# CH32H417 register map
Vendor: WCH Ltd.; File version: 1.2
Registers are 32-bit, read-write, reset 0x0 unless marked. A register's access mark holds for its fields unless they carry their own. Offsets are from the block's base; [hi:lo] are bit positions; {n}, {i} and the like mark numbered series; 'fields as' and 'values as' point back to an identical list.

## USBSS — USB3.0 ultra-high speed host /device controller
Base 0x40034000
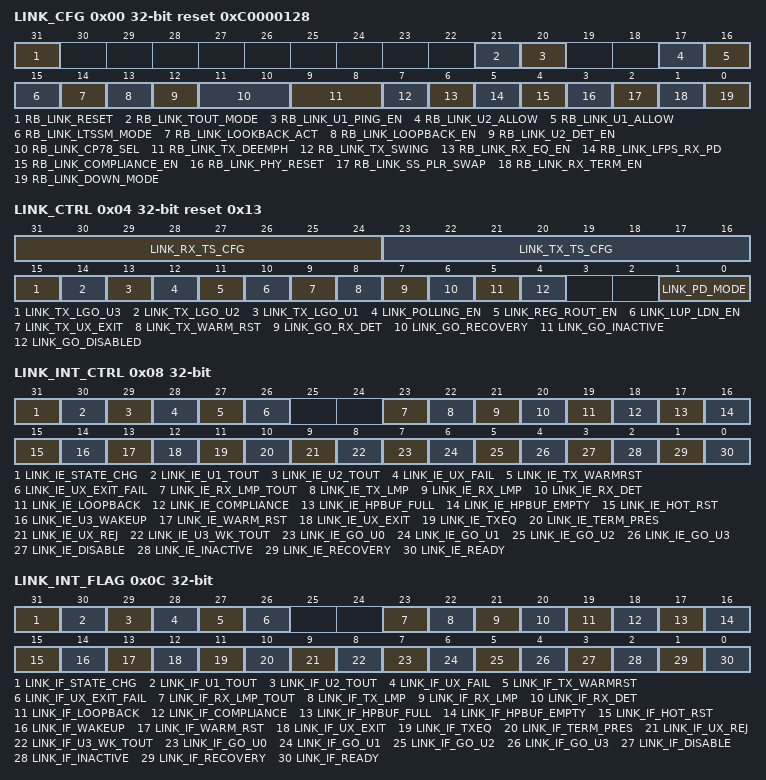
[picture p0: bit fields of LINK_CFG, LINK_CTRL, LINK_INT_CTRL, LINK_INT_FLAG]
0x00 LINK_CFG reset 0xC0000128 — LINK Configuration Register
  [31] RB_LINK_RESET — LINK reset, including the reset state machine and all interrupt flags, is highly effective
  [21] RB_LINK_TOUT_MODE — SPEC configure
  [20] RB_LINK_U1_PING_EN — Send PING_FPFS under U1 to enable
  [17] RB_LINK_U2_ALLOW — High validity, after receiving the LGO_U2, the response LXU allows to enter the U2 state, otherwise after receiving the LGO_U2, the response LXU refuses to enter the U2 state.
  [16] RB_LINK_U1_ALLOW — High validity, after receiving the LGO_U1, the response LAU allows to enter the U1 state, otherwise, after receiving the LGO_U1, the response LXU refuses to enter the U1 state
  [15] RB_LINK_LTSSM_MODE — The link state machine enters DISABLE mode
  [14] RB_LINK_LOOKBACK_ACT — It is used in LOOPBACK mode for the LOOPBACK master to control the pattern transmission (the LOOPBACK slave keeps 0), and the ACT is a high-level signal that lasts for a period of time.
  [13] RB_LINK_LOOPBACK_EN — The LOOPBACK enable bit is allowed, which is highly active, and can be used with the LOOKBACK enable in TX/RX_TS_CFG [3], both of which are valid before LINK can enter the LOOKBACK mode (used to enable the data loopback and error counting of the LOOPBACK slave, and the LOOPBACK master remains 0).
  [12] RB_LINK_U2_DET_EN — Detection mode of connected devices in U2 state
  [11:10] RB_LINK_CP78_SEL — In Compliance Pattern 7/8, send a length of consecutive 0 or consecutive 1
  [9:8] RB_LINK_TX_DEEMPH — Transmitter de-emphasis control
  [7] RB_LINK_TX_SWING — The transmitter signal swing control, low swing power consumption, but affect the transmission distance
  [6] RB_LINK_RX_EQ_EN — Receiver equalization enable control, optional protocol specifications
  [5] RB_LINK_LFPS_RX_PD — LFPS receive control, this bit is 1 to disable LFPS reception
  [4] RB_LINK_COMPLIANCE_EN — POLLING_LFPS timeout is in COMPLIANCE mode
  [3] RB_LINK_PHY_RESET — The PIPE interface is reset
  [2] RB_LINK_SS_PLR_SWAP — Exchange SSTX and SSRX polarities as follows
  [1] RB_LINK_RX_TERM_EN — Receiver Termination Resistance Control
  [0] RB_LINK_DOWN_MODE — Peripheral Type
0x04 LINK_CTRL access per field reset 0x13 — LINK control registers
  [31:24] LINK_RX_TS_CFG ro — Received Link Control
  [23:16] LINK_TX_TS_CFG rw — Send the link configuration of the TS1/TS2 training sequence
  [15] LINK_TX_LGO_U3 rw — After the bit is valid, the LGO_U3 is transmitted, and the hardware is automatically cleared
  [14] LINK_TX_LGO_U2 rw — After the bit is valid, the LGO_U2 is sent, the high is active, and the hardware is automatically cleared
  [13] LINK_TX_LGO_U1 rw — After the bit is valid, the LGO_U1 is sent, the high is active, and the hardware is automatically cleared
  [12] LINK_POLLING_EN rw — If the TERM is detected by the SS.RX_DETECT, a POLLING handshake will be performed after the software sets the bit to be valid
  [11] LINK_REG_ROUT_EN rw — Enable the routing function of the HUB, which is highly effective, with registers and no interfaces
  [10] LINK_LUP_LDN_EN rw — In the U0 state, if there is no data, whether to send LUP and LDN packets every 10us
  [9] LINK_TX_UX_EXIT rw — High validity, hardware automatic zeroing
  [8] LINK_TX_WARM_RST rw — High validity, cleared by software. A valid bit will send a warm-reset
  [7] LINK_GO_RX_DET rw — Before setting this bit, the PD_MODE should be set to P2 mode, and the LINK should be set to enter the SS.RX_DETECT, and the software will query TERM_PRESENT to know whether there is a connection or whether the connection is disconnected. High effectiveness, automatic clearing.
  [6] LINK_GO_RECOVERY rw — SET THE LINK TO ENTER SS.RECOVERY, WHICH IS HIGHLY EFFECTIVE, AND THE HARDWARE IS AUTOMATICALLY CLEARED.
  [5] LINK_GO_INACTIVE rw — SET THE LINK TO ENTER SS.INACTIVE, WHICH IS HIGHLY VALID, AND THE HARDWARE IS AUTOMATICALLY CLEARED
  [4] LINK_GO_DISABLED rw — SET LINK TO ENTER SS.DISABLED, WHICH IS HIGHLY VALID, AND REQUIRES SOFTWARE TO CLEAR
  [1:0] LINK_PD_MODE rw — Configure the current power mode of the PHY, corresponding to PO/P1/P2/P3 in the PIPE
0x08 LINK_INT_CTRL — LINK interrupt enable register
  [31] LINK_IE_STATE_CHG — Link State Machine Change Flag Interrupt Enabled
  [30] LINK_IE_U1_TOUT — U1 Timeout Interrupt Enabled
  [29] LINK_IE_U2_TOUT — U2 Timeout Interrupt Enabled
  [28] LINK_IE_UX_FAIL — UX Conversion Failure Interrupt Enabled
  [27] LINK_IE_TX_WARMRST — Send warm_reset end interrupt enabled
  [26] LINK_IE_UX_EXIT_FAIL — Exit UX failed to interrupt enabled
  [23] LINK_IE_RX_LMP_TOUT — Receive LMP Timeout Interrupt Enabled
  [22] LINK_IE_TX_LMP — If you successfully enter U0, you can send an HP packet to interrupt enable
  [21] LINK_IE_RX_LMP — Received Link Command Flag Interrupt Enabled
  [20] LINK_IE_RX_DET — The link enters the Rx.Detect state and is interrupted
  [19] LINK_IE_LOOPBACK — The link goes into loopback mode for testing and error isolation interrupt enablement
  [18] LINK_IE_COMPLIANCE — The link enters the compliance test, and the interrupt is enabled by the compatibility test or the physical layer conformance test
  [17] LINK_IE_HPBUF_FULL — BUF sends FIFO full interrupt enable
  [16] LINK_IE_HPBUF_EMPTY — BUF sends FIFO null interrupt enable
  [15] LINK_IE_HOT_RST — hot reset, which uses the reset interrupt enable of the TS1/TS2 ordered set
  [14] LINK_IE_U3_WAKEUP — In the U3 state, the Low Frequency Periodic Signal (LFPS) is received to wake up interrupt enabled
  [13] LINK_IE_WARM_RST — Warm reset (not connected) interrupt enabled with LPFS
  [12] LINK_IE_UX_EXIT — Request to exit UX is received Interrupt Enable
  [11] LINK_IE_TXEQ — LINK enters the POLLING_RXEQ for receiver equalization training interrupt enable
  [10] LINK_IE_TERM_PRES — LINK enters the RX_DETECT to detect the impedance of the remote receiver trace segment and detect the interrupt enabled
  [9] LINK_IE_UX_REJ — Transmit LGO_ Ux, receive LXU interrupt enabled that refuses to enter the Ux
  [8] LINK_IE_U3_WK_TOUT — Interrupt the U3 command when requesting to exit U3 command timeout
  [7] LINK_IE_GO_U0 — LINK is interrupted at U0 to enable the following
  [6] LINK_IE_GO_U1 — LINK is interrupted at U1 to enable the following
  [5] LINK_IE_GO_U2 — LINK is interrupted at U2 and enabled
  [4] LINK_IE_GO_U3 — LINK is enabled when the U3 interrupt is enabled
  [3] LINK_IE_DISABLE — LINK is disabled, interrupt enabled
  [2] LINK_IE_INACTIVE — LINK is enabled on INACTIVE interrupt
  [1] LINK_IE_RECOVERY — DUE TO ERROR LINK IN RECOVERY INTERRUPTED ENABLED
  [0] LINK_IE_READY — LINK is initialized, including two ports before (Header Sequence Number Advertisement) and (RX Headr Buffer Credit Advertisement) interrupt enabled
0x0C LINK_INT_FLAG — LINK Interrupt Flag Register
  [31] LINK_IF_STATE_CHG — link_reset reset to 0
  [30] LINK_IF_U1_TOUT — U1 timeout interrupted
  [29] LINK_IF_U2_TOUT — U2 timeout interrupted
  [28] LINK_IF_UX_FAIL — Enter the Ux failed to interrupt
  [27] LINK_IF_TX_WARMRST — send warm_reset to end interrupt
  [26] LINK_IF_UX_EXIT_FAIL — Exit UX fails to interrupt
  [23] LINK_IF_RX_LMP_TOUT — After the LINK initialization is complete, the Port Capabilities/Configuration LMPs timeout (20us) interrupt flag is exchanged.
  [22] LINK_IF_TX_LMP — After the LINK initialization is completed, the software is configured to send Port Capabilities LMP for port capability switching
  [21] LINK_IF_RX_LMP — Receive LMP Interrupt Flag
  [20] LINK_IF_RX_DET — After entering the RX_DETECT state interrupt flag, this position 1, the software sets the PWR_MODE to P2, ready for RX_DETECT
  [19] LINK_IF_LOOPBACK — LINK enters the LOOPBACK state and the LINK is interrupted.
  [18] LINK_IF_COMPLIANCE — LINK enters the COMPLIANCE state with an outage flag.
  [17] LINK_IF_HPBUF_FULL — Header Packet buffer full interrupt flag.
  [16] LINK_IF_HPBUF_EMPTY — he device receives the HOT RESET interrupt flag
  [15] LINK_IF_HOT_RST — The device receives the HOT RESET interrupt flag
  [14] LINK_IF_WAKEUP — The power supply is in P3 mode and the LFPS signal interrupt flag is detected.
  [13] LINK_IF_WARM_RST — The WARM RESET status change (active-> inactive, or invalid->active) interrupt flag received by the device.
  [12] LINK_IF_UX_EXIT — LINK receives the LFPS ready to exit U1/U2/U3 request interrupt flag
  [11] LINK_IF_TXEQ — LINK enters TXEQ state interrupt flag: INDICATE THAT THE POLLING HANDSHAKE IS COMPLETE, AND WAIT FOR THE SOFTWARE TO SET THE PWR_MODE TO P0 IN ORDER TO ENTER THE TXEQ PHASE.
  [10] LINK_IF_TERM_PRES — The TERM disconnected or disconnected flag was detected
  [9] LINK_IF_UX_REJ — LINK refuses to enter the low-power mode (U1/U2) interrupt flag.
  [8] LINK_IF_U3_WK_TOUT — Wake up from U3 to timeout interrupt flag (10ms).
  [7-n] LINK_IF_GO_U{n} (n=0..3) — LINK enters the U{n} state interrupt flag.
  [3] LINK_IF_DISABLE — LINK INTO SS.DISABLE STATE INTERRUPT FLAG
  [2] LINK_IF_INACTIVE — LINK ENTERS THE SS.ACTIVE STATE INTERRUPT FLAG
  [1] LINK_IF_RECOVERY — LINK INTO THE SS.RECOVERY STATE INTERRUPT FLAG
  [0] LINK_IF_READY — LINK enters the U0 state and completes LINK initialization of the interrupt flag.
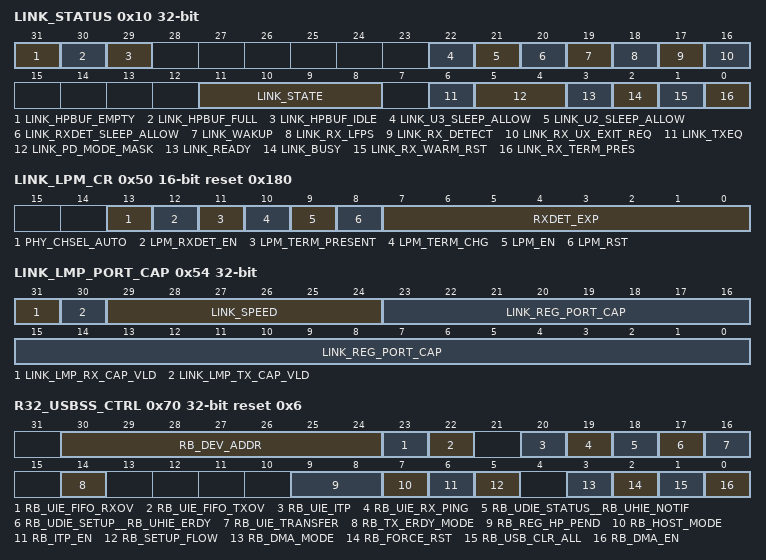
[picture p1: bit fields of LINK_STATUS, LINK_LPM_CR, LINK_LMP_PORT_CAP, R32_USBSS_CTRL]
0x10 LINK_STATUS ro
  [31] LINK_HPBUF_EMPTY — The HP buffer is empty.
  [30] LINK_HPBUF_FULL — The HP buffer is full.
  [29] LINK_HPBUF_IDLE — BUF sends the status of the FIFO IDLE
  [22] LINK_U3_SLEEP_ALLOW — The link is in the U3 state and sleep is allowed
  [21] LINK_U2_SLEEP_ALLOW — The link is in the U2 state and sleep is allowed.
  [20] LINK_RXDET_SLEEP_ALLOW — The link is in the RXDET state, allowing sleep.
  [19] LINK_WAKUP — A link wake-up signal is received.
  [18] LINK_RX_LFPS — The link receives an LFPS signal.
  [17] LINK_RX_DETECT — The link is at P2 and is in rx_detect.
  [16] LINK_RX_UX_EXIT_REQ — Received a request to exit Ux
  [11:8] LINK_STATE — Link Status
  [6] LINK_TXEQ — The link is in POLLING_RXEQ.
  [5:4] LINK_PD_MODE_MASK — Link Power Status
  [3] LINK_READY — When the LINK enters the U0 state, the position 1 exits the U0 state after the initialization (broadcast) is completed, and the bit is automatically cleared.
  [2] LINK_BUSY — When the LINK is busy, the bit is 1 when the switchover is PD_MODE, and the hardware will automatically clear the link after the switchover is completed.
  [1] LINK_RX_WARM_RST — A valid warm-reset signal is received from the host (the hardware automatically pulls up after receiving the host's warm_reset 18ms).
  [0] LINK_RX_TERM_PRES — After RX_DETECT, if a receive termination resistor is present, the bit is 1
0x17 LINK_ITP_PRE 8-bit ro reset 0x80 — LINK ITP Timeout Mode Register
  [7:0] ITP_PRE — ITP Timeout Mode
0x1D LINK_U2_INACT_TIMER 8-bit — LINK U2 Inactivity Timeout Counter Threshold Register
  [7:0] U2_INACTIVE_TIMER — The value of the inactivity timeout counter threshold for U2
0x28 LINK_U1_WKUP_FILTER 8-bit reset 0x4A — U1 wakes up the LFPS Duration Register
  [7:0] U1_WKUP_FILTER — The duration of the LFPS received by U1 when exiting. When the receiving LFPS reaches this time, the received U1 EXIT is considered valid, and the handshake is successful when the transmitting LFPS_last is raised, which is 600ns by default U1_WKUP_FILTER [7]: the unit of time that controls the U1_WKUP_FILTER [6:0]
0x2C LINK_U2_WKUP_FILTER 8-bit reset 0x2 — U2 wakes up the LFPS Duration Register
  [7:0] U2_WKUP_FILTER — When the receiving LFPS reaches this time, the sending LFPS_last is pulled up and the handshake is successful, and the received U2 EXIT can be considered valid with the duration of (n)us, the default is 2us.
0x30 LINK_U3_WKUP_FILTER 8-bit reset 0x64 — U3 wakes up the LFPS validity duration register
  [7:0] U3_WKUP_FILTER — When the receiving LFPS reaches this time, the LFPS_last is raised, and the handshake is successful, and the received U3 EXIT is considered valid for (n)us, with a default of 100us.
0x40 LINK_ISO_DLY 16-bit reset 0x28 — LINK Synchronous Delay Register
  [15:0] LINK_ISOCH_DLY — The delay time for the serial bitstream to parse to the parallel data is 40ns by default, and the SET ISOCH DELAY host sends this information to the device when enumerated, and writes the delay information to the register as the device, and the lower 3 bits of the register are invalid (because the clock frequency is 125MHz, the delay time needs to be set to 8*n).
0x50 LINK_LPM_CR 16-bit reset 0x180 — Link Power Management Registers
  [13] PHY_CHSEL_AUTO — Automatic selection of the PHY layer transceiver channel type
  [12] LPM_RXDET_EN — When the lpm count reaches the expected value RXDET_EXP it is confirmed that a device is connected to the PHY, this bit is raised.
  [11] LPM_TERM_PRESENT — The PHY layer detects a device connection.
  [10] LPM_TERM_CHG — The connected device changes, plugs in the device or unplugs the device.
  [9] LPM_EN — LPM Enable
  [8] LPM_RST — Reset signal for LPM related register
  [7:0] RXDET_EXP — Detects external device counter registers.
0x54 LINK_LMP_PORT_CAP ro — PORT_CAP Registers
  [31] LINK_LMP_RX_CAP_VLD — A valid PORT_CAP-LMP is received, and the protocol stipulates that the two LINK parties exchange PORT_CAP-LMP within 20 years after entering the U0 state.
  [30] LINK_LMP_TX_CAP_VLD — PORT Capability configuration completion flag
  [29:24] LINK_SPEED — [24] Position 1, indicating that the supported device supports USB3.2 Gen1 (5Gbps).
  [23:0] LINK_REG_PORT_CAP — link port configure
0x58 LINK_LMP_RX_DATA0 ro — LMP receives data 0 register
  [31:0] LINK_LMP_RX_DATA0 — Once the LMP is received, the HP data is stored in this register [31:0]
0x5C LINK_LMP_RX_DATA1 ro — LMP receives data 1 register
  [31:0] LINK_LMP_RX_DATA1 — Once the LMP is received, the HP data is stored in this register [63:32]
0x60 LINK_LMP_RX_DATA2 ro — LMP receives data 2 register
  [31:0] LINK_LMP_RX_DATA1 — Once the LMP is received, the HP data is stored in this register [95:64]
{0x64+4i} LINK_LMP_TX_DATA{i} (i=0..2) — USB Custom HP Data {i} Register
  [31:0] LINK_LMP_TX_DATA{i} — The data of the user-defined HP is sent [{32i+31}:{32i}]
0x70 R32_USBSS_CTRL reset 0x6 — USBSS Control Register
  [30:24] RB_DEV_ADDR — Host Mode
  [23] RB_UIE_FIFO_RXOV — Receive FIFO overflow interrupt enabled
  [22] RB_UIE_FIFO_TXOV — Sending FIFO overflow interrupt enables
  [20] RB_UIE_ITP — Send ITP to complete interrupt enable
  [19] RB_UIE_RX_PING — Interrupt Enabled for Receiving PING-TP
  [18] RB_UDIE_STATUS__RB_UHIE_NOTIF — Device mode: Receiving STATUS transaction completion interrupt enabled; Host mode: Interrupt enabled for receiving DEV_NOTIF-TP
  [17] RB_UDIE_SETUP__RB_UHIE_ERDY — Device Mode: Receive SETUP Transaction Completion Interrupt Enabled; Host mode:Receive SETUP Transaction Completion Interrupt Enabled
  [16] RB_UIE_TRANSFER — USB Transaction Completion Interrupt Enabled
  [14] RB_TX_ERDY_MODE — Use in device mode
  [9:8] RB_REG_HP_PEND — Packet Pending control bit for sending TP/DP packets
  [7] RB_HOST_MODE — USB Operating Mode Selection Bits
  [6] RB_ITP_EN — In host mode, send ITP enabled
  [5] RB_SETUP_FLOW — SETUP transaction throttling
  [3] RB_DMA_MODE — When DPH is transmitted in bursts, the next packet of data status
  [2] RB_FORCE_RST — The protocol layer and FIFO module are reset and need to be cleared by software.
  [1] RB_USB_CLR_ALL — Reset all software configuration registers, high validity, software clearance required
  [0] RB_DMA_EN — Enable DMA
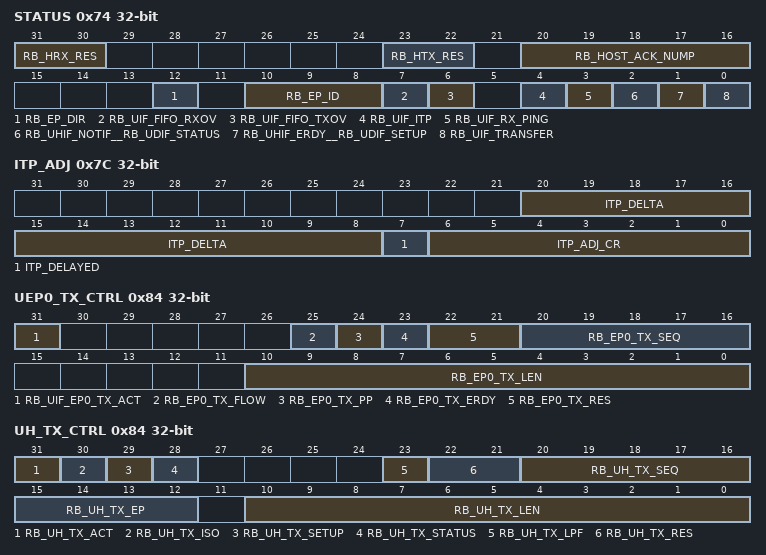
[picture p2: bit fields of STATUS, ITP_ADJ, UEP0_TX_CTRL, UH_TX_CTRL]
0x74 STATUS — USBSS Status Register
  [31:30] RB_HRX_RES — A reply TP is received from the device back
  [23:22] RB_HTX_RES — Received a reply TP from the device returning
  [20:16] RB_HOST_ACK_NUMP — This bit is invalid for synchronous transmission, and is defined as follows in Control Transfer, Block Transfer, and Interrupt Transfer
  [12] RB_EP_DIR — The direction of the endpoint that currently has an interrupt flag for transmission completion,
  [10:8] RB_EP_ID — If multiple endpoints have interrupt flags at the same time, the order of endpoint priority is as follows
  [7] RB_UIF_FIFO_RXOV — Receive FIFO overflow interrupt flag
  [6] RB_UIF_FIFO_TXOV — Send FIFO overflow interrupt flag
  [4] RB_UIF_ITP — Send the ITP Complete Interrupt flag
  [3] RB_UIF_RX_PING — Receive PING-TP Complete Interrupt Flag
  [2] RB_UHIF_NOTIF__RB_UDIF_STATUS — Host Mode: Receive DEV_NOTIF-TP Complete Interrupt Flag; Device Mode: Receive STATUS Transaction Completion Interrupt Flag
  [1] RB_UHIF_ERDY__RB_UDIF_SETUP — Host Mode: Receive ERDY-TP Complete Interrupt Flag; Device Mode: Receive SETUP Transaction Completion Interrupt Flag
  [0] RB_UIF_TRANSFER — USB Transaction Completion Interrupt Flag
0x78 ITP ro — Interval Registers for ITP packets in USB
  [13:0] REG_ITP_INTERVAL — Bus interval Counter field in the received ITP.
0x7C ITP_ADJ ro — Interval Adaptive Registers for ITP packets in USB
  [20:8] ITP_DELTA — The higher 13-bit delta of the ITS in the ITP received in device mode indicates the time difference from the start of the current ITP packet to the previous bus interval boundary.
  [7] ITP_DELAYED — In device mode, the Delayed bit of Link Control Word in the received ITP is 1 when the ITP is delayed.
  [6:0] ITP_ADJ_CR — In device mode, the Bus Interval Adjustment Control field in the received ITP should be 0 after power-on reset or device disconnection.
0x80 UEP_TX_EN 16-bit reset 0x1 — Endpoint Sends Enable Register
  [15:1] RB_EP_TX_EN — Endpoints 1~15 upload enabled
0x82 UEP_RX_EN 16-bit reset 0x1 — Endpoint Receive Enable Register
  [15:1] RB_EP_RX_EN — Endpoints 1~15 downpass enabled
0x84 UEP0_TX_CTRL access per field — Endpoint 0 sends control registers
  [31] RB_UIF_EP0_TX_ACT rw — The upload transaction is interrupted, the software writes 0 to zero, and the hardware sets 1.
  [25] RB_EP0_TX_FLOW ro — A sign that completes the NRDY-TP send (answer)
  [24] RB_EP0_TX_PP ro — The PP bit in the received ACK-TP
  [23] RB_EP0_TX_ERDY rw — ERDY received
  [22:21] RB_EP0_TX_RES rw — Response to ACK-TP
  [20:16] RB_EP0_TX_SEQ rw — The current sequence number of the endpoint, which is aotomatically reset after receiving the SETUP transaction
  [10:0] RB_EP0_TX_LEN rw — Endpoint transmits length registers with a maximum value of 512B
0x84 UH_TX_CTRL (alternate view of UEP0_TX_CTRL) — Host Transmit Control Registers
  [31] RB_UH_TX_ACT — The IN transaction completes the interrupt flag, the software writes 0 to zero, and the hardware sets 1.
  [30] RB_UH_TX_ISO — The host prepares to send ISO packets.
  [29] RB_UH_TX_SETUP — Indicates that the packet sent by the host is a Setup packet, and the setup flag is set.
  [28] RB_UH_TX_STATUS — Indicates that the packet sent by the host is STATUS TP.
  [23] RB_UH_TX_LPF — For burst transmissions, this bit simply represents the LPF/EOB of the last packet, and the LPF/EOB of the preceding packet uses a fixed value of 0.
  [22:21] RB_UH_TX_RES — Response to DPH+DPP
  [20:16] RB_UH_TX_SEQ — The SEQ _NUM for which the endpoint receives the packet, the hardware automatically adds 1, except for endpoint 0
  [15:12] RB_UH_TX_EP — Indicates the destination of the packet sent in host mode (the target endpoint number of the device)
  [10:0] RB_UH_TX_LEN — The endpoint receives the length register, which for burst transmissions indicates the packet length of the last packet of the burst transmission, and the other packets must be 1024B as specified in the protocol.
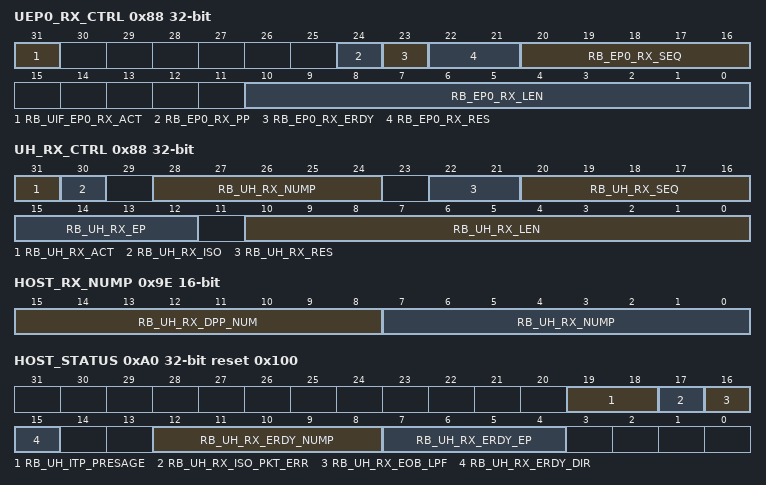
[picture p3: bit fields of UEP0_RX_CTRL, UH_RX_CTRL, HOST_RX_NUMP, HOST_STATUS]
0x88 UEP0_RX_CTRL access per field — Endpoint 0 receives control registers
  [31] RB_UIF_EP0_RX_ACT rw — Upload the transaction completion interrupt flag, the software writes 0 to zero, and the hardware sets 1
  [24] RB_EP0_RX_PP ro — PP bits in the received DPH
  [23] RB_EP0_RX_ERDY rw — ERDY received
  [22:21] RB_EP0_RX_RES rw — Response to DPH
  [20:16] RB_EP0_RX_SEQ rw — The sequence number of the endpoint expects to accept
  [10:0] RB_EP0_RX_LEN ro — The endpoint receives the length register
0x88 UH_RX_CTRL access per field (alternate view of UEP0_RX_CTRL) — Host receives control registers
  [31] RB_UH_RX_ACT rw — The OUT transaction completes the interrupt flag, the software writes 0 to zero, and the hardware sets 1
  [30] RB_UH_RX_ISO ro — Received Packets (DPP) are transmitted synchronously
  [28:24] RB_UH_RX_NUMP rw — The number of packets (DPP) that the endpoint is capable of receiving (burst transmission)
  [22:21] RB_UH_RX_RES ro — Response to DPH+DPP or STATUS-TP
  [20:16] RB_UH_RX_SEQ rw — The SEQ _NUM that the endpoint expects to receive, the hardware automatically adds 1, except for endpoint 0
  [15:12] RB_UH_RX_EP rw — Indicates the source (device endpoint number) from which the packet was received in host mode
  [10:0] RB_UH_RX_LEN ro — The endpoint receives the length register, which for burst transmissions indicates the packet length of the last packet of the burst transmission, and the other packets must be 1024B as specified in the protocol
0x8C UH_TX_DMA_U3EP0_TX_DMA — Send buffer address registers
  [31:0] U3EP0_TX_DMA — Host Mode:The start address of the host sending buffer. Device Mode:Endpoint 0 sends the start of the buffer.
0x90 UH_RX_DMA_U3EP0_RX_DMA — Receive buffer address registers
  [31:0] U3EP0_RX_DMA — Host Mode:The start address of the host receiving buffer. Device Mode:Endpoint 0 receives the start of the buffer.
0x94 UH_TX_DMA_OFS reset 0x400 — Host Transmit Address Offset Register
  [31:0] RB_UH_TX_DMA_OFS — After the host sends the DMA, the size of the DMA address offset
0x98 UH_RX_DMA_OFS reset 0x400 — Host Receive Address Offset Register
  [31:0] RB_UH_RX_DMA_OFS — After the host receives it, the DMA's address is offset by a large amount.
0x9E HOST_RX_NUMP 16-bit — The host receives the NUMP register
  [15:8] RB_UH_RX_DPP_NUM — The number of DPPs that have been accepted by the host.
  [7:0] RB_UH_RX_NUMP — The number of packets that the host expects to receive, if it is a synchronous transmission, will automatically subtract 1 from the hardware for each packet it receives.
0xA0 HOST_STATUS ro reset 0x100 — Host Status Registers
  [19:18] RB_UH_ITP_PRESAGE — In host mode, this bit indicates the time when the ITP packet was sent
  [17] RB_UH_RX_ISO_PKT_ERR — A CRC error was received for the packet (DPP) during synchronous transmission
  [16] RB_UH_RX_EOB_LPF — This bit represents the EOB/LPF status in the received packet
  [15] RB_UH_RX_ERDY_DIR — ERDY is received from the device, and the segment represents the direction of the endpoint
  [12:8] RB_UH_RX_ERDY_NUMP — ERDY received from the device, which indicates the number of packets that can be sent/received by the device's corresponding endpoint
  [7:4] RB_UH_RX_ERDY_EP — ERDY is received from the device, and the segment represents the endpoint number of the device ERDY
0xA4 HOST_TX_FC_STATUS 16-bit — The host endpoint sends flow control register
  [15:1] EPx_TX_FC — The flow control status of the host to send endpoints 1-15.
0xA6 HOST_RX_FC_STATUS 16-bit — The host endpoint receives the flow control register
  [15:1] EPx_RX_FC — The flow control status of the host to receiving endpoints 1-15
{0xA8+4i} TP_RX_DATA{i} ro (i=0..2) — DEV_NOTIF-TP Data {i} Register
  [31:0] USB3_NOTIF_DATA{i} — After the DEV_NOTIF-TP is received, the HP data is stored in this register
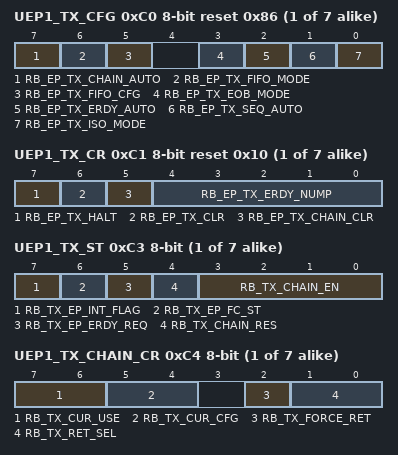
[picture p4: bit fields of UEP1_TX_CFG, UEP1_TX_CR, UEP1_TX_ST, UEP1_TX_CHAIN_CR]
{0xA0+0x20*i} UEP{i}_TX_CFG 8-bit reset 0x86 (i=1..7) — Endpoint {i} Configuration Register
  [7] RB_EP_TX_CHAIN_AUTO — CHAIN automatically switches modes, and this mode is recommended
  [6] RB_EP_TX_FIFO_MODE — If the bit is 1, the current endpoint uses FIFO mode, and the start and end addresses of the FIFO should be configured before the bit is 1.
  [5] RB_EP_TX_FIFO_CFG — Access offset address 0xC~0xF, and the operation object
  [3] RB_EP_TX_EOB_MODE — If a short packet is sent, EOB/LPF=0 in ACK-TP;If a short packet is sent, EOB/LPF=1 in ACK-TP
  [2] RB_EP_TX_ERDY_AUTO — ERDY automatic mode, the hardware will send ERDY, no software control required; It is recommended that the synchronization endpoint zero out this bit.
  [1] RB_EP_TX_SEQ_AUTO — 1: It is forbidden to write R16_EPn_ST->EP_SEQ_NUM software; 0: allows the software to write R16_EPn_ST->EP_SEQ_NUM.
  [0] RB_EP_TX_ISO_MODE — A value of 1 indicates that the current endpoint is a synchronous endpoint
{0xA1+0x20*i} UEP{i}_TX_CR 8-bit reset 0x10 (i=1..7) — Endpoint {i} control register
  [7] RB_EP_TX_HALT — Endpoint Stop, High Validity, Endpoint Stop Answering STALL to DPH.
  [6] RB_EP_TX_CLR — Write 1 clears all configuration values and status of the endpoint, except for UEP_CFG.
  [5] RB_EP_TX_CHAIN_CLR — Write 1 clears all CHAIN configuration values and statuses
  [4:0] RB_EP_TX_ERDY_NUMP — The nump field of ERDY-TP is sent by the hardware, and the value is generally set to the number of supported bursts. For example, if you support 16 bursts, the value of this field is 16.
{0xA2+0x20*i} UEP{i}_TX_SEQ 8-bit (i=1..7) — Endpoint {i} Serial Number Register
  [4:0] RB_TX_EP_SEQ_NUM — The current serial number of the endpoint, writable in non-SEQ_AUTO mode, read-only in SEQ_AUTO mode
{0xA3+0x20*i} UEP{i}_TX_ST 8-bit access per field (i=1..7) — Endpoint {i} status register
  [7] RB_TX_EP_INT_FLAG ro — The current break flag for the endpoint, the bit is read-only, and all CHAIN_IF are 0 if the bit is 0, otherwise it is 1.
  [6] RB_TX_EP_FC_ST rw — The endpoint is in the current throttling state, and write 1 is cleared to zero.
  [5] RB_TX_EP_ERDY_REQ rw — Indicates that the ERDY is currently being sent; Writing 1 to that bit will send ERDY, which is used in non-ERDY_AUTO mode.
  [4] RB_TX_CHAIN_RES ro — CHAIN response state, corresponding to 4 separate CHAINS
  [3:0] RB_TX_CHAIN_EN ro — The CHAIN enabled state, which corresponds to 4 independent CHAINS.
{0xA4+0x20*i} UEP{i}_TX_CHAIN_CR 8-bit access per field (i=1..7) — Endpoint {i} CHAIN control register
  [7:6] RB_TX_CUR_USE ro — The CHAIN serial number currently in use
  [5:4] RB_TX_CUR_CFG ro — The chain serial number of the current configuration.
  [2] RB_TX_FORCE_RET rw — This bit effectively forces the return of the selected CHAIN state machine configuration
  [1:0] RB_TX_RET_SEL rw — When the FORCE_RET is valid, this bit indicates the returned CHAIN status and configuration
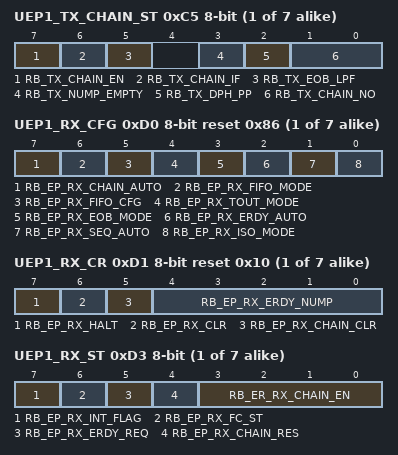
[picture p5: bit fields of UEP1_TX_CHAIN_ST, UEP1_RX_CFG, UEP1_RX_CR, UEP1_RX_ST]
{0xA5+0x20*i} UEP{i}_TX_CHAIN_ST 8-bit access per field (i=1..7) — Endpoint {i} CHAIN state register
  [7] RB_TX_CHAIN_EN ro — The currently used CHAIN enables the automatic hardware setting of 1 after the UEP_CHAIN_NUMP register is configured, and the CHAIN is automatically cleared to zero after the transmission is completed
  [6] RB_TX_CHAIN_IF rw — This bit is only written, and 1 is written to release the current CHAIN_IF
  [5] RB_TX_EOB_LPF rw — EOB/LPF bits in the last packet of DPH in the current CHAIN
  [3] RB_TX_NUMP_EMPTY ro — IF THE NUMP IN THE CHAIN IS 0, THE POSITION IS 1
  [2] RB_TX_DPH_PP rw — The status of the PP bits in the currently received DPH
  [1:0] RB_TX_CHAIN_NO rw — The serial number of the CHAIN that is currently interrupting
{0xA6+0x20*i} UEP{i}_TX_CHAIN_LEN 16-bit ro (i=1..7) — Endpoint {i} CHAIN sends the last packet length
  [10:0] CHAIN_TX_LEN — The length of the last packet sent by the CHAIN
{0xA8+0x20*i} UEP{i}_TX_CHAIN_EXP_NUMP 16-bit (i=1..3) — Number of NUMPs expected to be sent by endpoint {i}
  [7:0] TX_CHAIN_EXP_NUMP — The number of DPP packets that can be sent by the currently completed CHAIN
0xC9 UEP1_TX_CHAIN_NUMP 8-bit — Number of NUMPs has been sent by endpoint n
  [7:0] TX_CHAIN_NUMP — The number of DPP packets that have been transmitted
{0xAA+0x20*i} UEP{i}_TX_DMA_OFS 16-bit (i=1..3) — DMA offset length for endpoint {i}
  [15:0] CHAIN_TX_DMA_OFS — The offset address of the DPP in that CHAIN
{0xAC+0x20*i} UEP{i}_TX_DMA (i=1..3) — DMA start address for endpoint {i}
  [31:0] CHAIN_TX_DMA — Normal mode:The DMA start address of the CHAIN to send data. FIFO mode:16~23 bits of the FIFO start address in SRAM;The FIFO end address is 16~23 bits of the mapped address in SRAM.
{0xB0+0x20*i} UEP{i}_RX_CFG 8-bit reset 0x86 (i=1..7) — Endpoint {i} Configuration Register
  [7] RB_EP_RX_CHAIN_AUTO — CHAIN automatically switches modes, and this mode is recommended
  [6] RB_EP_RX_FIFO_MODE — If the bit is 1, the current endpoint uses FIFO mode, and the start and end addresses of the FIFO should be configured before the bit is 1.
  [5] RB_EP_RX_FIFO_CFG — Access offset address 0xC~0xF, and the operation object
  [4] RB_EP_RX_TOUT_MODE — This bit is 1, and when a continuous burst packet is received, PP=1 and not a short packet is not received, and DPH is not received after the timeout, resulting in TOUT_IF interrupt
  [3] RB_EP_RX_EOB_MODE — This bit is 1, and when a short packet or DP(PP=0) is received, clearing all CHAIN_EN will result in an NRDY response to the subsequent DPH; Software reconfiguration required.
  [2] RB_EP_RX_ERDY_AUTO — ERDY automatic mode, the hardware will send ERDY, no software control required; It is recommended that the synchronization endpoint zero out this bit.
  [1] RB_EP_RX_SEQ_AUTO — 1: It is forbidden to write R16_EPn_ST->EP_SEQ_NUM software; 0: allows the software to write R16_EPn_ST->EP_SEQ_NUM.
  [0] RB_EP_RX_ISO_MODE — A value of 1 indicates that the current endpoint is a synchronous endpoint
{0xB1+0x20*i} UEP{i}_RX_CR 8-bit reset 0x10 (i=1..7) — Endpoint {i} control register
  [7] RB_EP_RX_HALT — Endpoint Stop, High Validity, Endpoint Stop Answering STALL to DPH.
  [6] RB_EP_RX_CLR — Write 1 clears all configuration values and status of the endpoint, except for UEP_CFG.
  [5] RB_EP_RX_CHAIN_CLR — Write 1 clears all CHAIN configuration values and statuses
  [4:0] RB_EP_RX_ERDY_NUMP — The nump field of ERDY-TP is sent by the hardware, and the value is generally set to the number of supported bursts. For example, if you support 16 bursts, the value of this field is 16.
{0xB2+0x20*i} UEP{i}_RX_SEQ 8-bit (i=1..7) — Endpoint {i} Serial Number Register
  [4:0] RB_EP_RX_SEQ_NUM — The current serial number of the endpoint, writable in non-SEQ_AUTO mode, read-only in SEQ_AUTO mode
{0xB3+0x20*i} UEP{i}_RX_ST 8-bit access per field (i=1..7) — Endpoint {i} status register
  [7] RB_EP_RX_INT_FLAG ro — The current break flag for the endpoint, the bit is read-only, and all CHAIN_IF are 0 if the bit is 0, otherwise it is 1.
  [6] RB_EP_RX_FC_ST rw — The endpoint is in the current throttling state, and write 1 is cleared to zero.
  [5] RB_EP_RX_ERDY_REQ rw — Indicates that the ERDY is currently being sent; Writing 1 to that bit will send ERDY, which is used in non-ERDY_AUTO mode.
  [4] RB_EP_RX_CHAIN_RES ro — CHAIN response state, corresponding to 4 separate CHAINS
  [3:0] RB_ER_RX_CHAIN_EN ro — The CHAIN enabled state, which corresponds to 4 independent CHAINS.
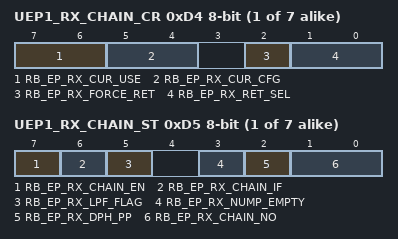
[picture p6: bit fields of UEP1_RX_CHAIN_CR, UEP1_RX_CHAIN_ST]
{0xB4+0x20*i} UEP{i}_RX_CHAIN_CR 8-bit access per field (i=1..7) — Endpoint {i} CHAIN control register
  [7:6] RB_EP_RX_CUR_USE ro — The CHAIN serial number currently in use
  [5:4] RB_EP_RX_CUR_CFG ro — The chain serial number of the current configuration.
  [2] RB_EP_RX_FORCE_RET rw — This bit effectively forces the return of the selected CHAIN state machine configuration
  [1:0] RB_EP_RX_RET_SEL rw — When the FORCE_RET is valid, this bit indicates the returned CHAIN status and configuration
{0xB5+0x20*i} UEP{i}_RX_CHAIN_ST 8-bit access per field (i=1..7) — Endpoint {i} CHAIN state register
  [7] RB_EP_RX_CHAIN_EN ro — The currently used CHAIN enables the automatic hardware setting of 1 after the UEP_CHAIN_NUMP register is configured, and the CHAIN is automatically cleared to zero after the transmission is completed
  [6] RB_EP_RX_CHAIN_IF rw — This bit is only written, and 1 is written to release the current CHAIN_IF
  [5] RB_EP_RX_LPF_FLAG rw — Only the synchronous downhaul endpoint is used to currently receive the LPF status in the DPH.
  [3] RB_EP_RX_NUMP_EMPTY ro — IF THE NUMP IN THE CHAIN IS 0, THE POSITION IS 1
  [2] RB_EP_RX_DPH_PP rw — The status of the PP bits in the currently received DPH
  [1:0] RB_EP_RX_CHAIN_NO rw — The serial number of the CHAIN that is currently interrupting
{0xB6+0x20*i} UEP{i}_RX_CHAIN_LEN 16-bit ro (i=1..7) — Endpoint {i} CHAIN sends the last packet length
  [10:0] RB_EP_RX_CHAIN_RX_LEN — The length of the currently completed CHAIN to the last packet.
{0xB8+0x20*i} UEP{i}_RX_CHAIN_MAX_NUMP 8-bit ro (i=1..7) — Number of NUMPs that Endpoint {i} can receive
  [7:0] RX_CHAIN_MAX_NUMP — The number of DPP packets that can be received by the CHAIN
0xD9 UEP1_RX_CHAIN_NUMP 8-bit ro — Number of NUMPs has been received by endpoint 1
  [7:0] TX_CHAIN_NUMP — The number of DPP packets that has received
0xDA UEP1_RX_DMA_OFS 16-bit ro — DMA offset length for endpoint 1
  [15:0] CHAIN_DMA_OFS — The offset address of the DPP in that CHAIN
0xDC UEP1_RX_DMA — DMA start address for endpoint 1
  [31:0] CHAIN_RX_DMA — Normal mode:The DMA start address of the CHAIN to receive data. FIFO mode:16~23 bits of the FIFO start address in SRAM;The FIFO end address is 16~23 bits of the mapped address in SRAM.
0xE9 UEP2_TX_CHAIN_NUMP 8-bit — Number of NUMPs has been sent by endpoint 2
  fields as UEP1_TX_CHAIN_NUMP
0xF9 UEP2_RX_CHAIN_NUMP 8-bit ro — Number of NUMPs has been received by endpoint 2
  [7:0] TX_CHAIN_NUMP — The number of DPP packets that has received
{0xBA+0x20*i} UEP{i}_RX_DMA_OFS 16-bit ro (i=2..7) — DMA offset length for Endpoint {i}
  [15:0] CHAIN_DMA_OFS — The offset address of the DPP in that CHAIN
{0xBC+0x20*i} UEP{i}_RX_DMA (i=2..7) — DMA start address for Endpoint {i}
  fields as UEP1_RX_DMA
0x109 UEP3_TX_CHAIN_NUMP 8-bit — Number of NUMPs has been sent by endpoint 3
  fields as UEP1_TX_CHAIN_NUMP
{0xB9+0x20*i} UEP{i}_RX_CHAIN_NUMP 8-bit ro (i=3..7) — Number of NUMPs has been received by Endpoint {i}
  [7:0] TX_CHAIN_NUMP — The number of DPP packets that has received
{0xA8+0x20*i} UEP{i}_TX_CHAIN_EXP_NUMP 16-bit (i=4..7) — Number of NUMPs expected to be sent by Endpoint {i}
  fields as UEP1_TX_CHAIN_EXP_NUMP
{0xA9+0x20*i} UEP{i}_TX_CHAIN_NUMP 8-bit (i=4..7) — Number of NUMPs has been sent by Endpoint {i}
  fields as UEP1_TX_CHAIN_NUMP
{0xAA+0x20*i} UEP{i}_TX_DMA_OFS 16-bit (i=4..7) — DMA offset length for Endpoint {i}
  fields as UEP1_TX_DMA_OFS
{0xAC+0x20*i} UEP{i}_TX_DMA (i=4..7) — DMA start address for Endpoint {i}
  fields as UEP1_TX_DMA
